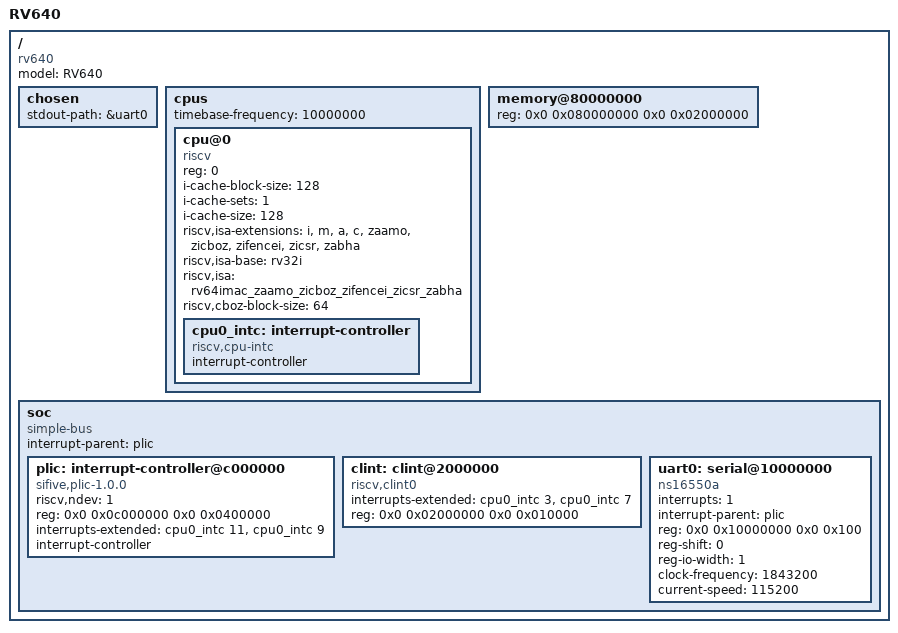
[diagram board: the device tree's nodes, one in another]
/dts-v1/;

/ {
	#address-cells = <2>;
	#size-cells = <2>;
	compatible = "rv640";
	model = "RV640";

	chosen {
		stdout-path = &uart0;
//		bootargs = "earlycon=ns16550a,mmio,0x10000000 console=ttyS0,115200";
	};

	cpus {
		#address-cells = <1>;
		#size-cells = <0>;
		timebase-frequency = <10000000>;

		cpu@0 {
			device_type = "cpu";
			reg = <0>;
			status = "okay";
			compatible = "riscv";
			i-cache-block-size = <128>;
			i-cache-sets = <1>;
			i-cache-size = <128>;
			riscv,isa-extensions = "i", "m", "a", "c", "zaamo", "zicboz", "zifencei", "zicsr", "zabha";
			riscv,isa-base = "rv32i";
			riscv,isa = "rv64imac_zaamo_zicboz_zifencei_zicsr_zabha";
			riscv,cboz-block-size = <64>;
//			mmu-type = "riscv,sv57";
			cpu0_intc: interrupt-controller {
				#interrupt-cells = <1>;
				interrupt-controller;
				compatible = "riscv,cpu-intc";
			};
		};
	};

	memory@80000000 {
		device_type = "memory";
		reg = <0x0 0x080000000 0x0 0x02000000>;
	};

	soc {
		#address-cells = <2>;
		#size-cells = <2>;
		compatible = "simple-bus";
		interrupt-parent = <&plic>;
		ranges;

		plic: interrupt-controller@c000000 {
			riscv,ndev = <1>;
			reg = <0x0 0x0c000000 0x0 0x0400000>;
			interrupts-extended = <&cpu0_intc 11>, <&cpu0_intc 9>;
			interrupt-controller;
			compatible = "sifive,plic-1.0.0";
			#address-cells = <0>;
			#interrupt-cells = <1>;
		};

		clint: clint@2000000 {
			interrupts-extended = <&cpu0_intc 3>, <&cpu0_intc 7>;
			reg = <0x0 0x02000000 0x0 0x010000>;
			compatible = "riscv,clint0";
		};

		uart0: serial@10000000 {
			compatible = "ns16550a";
			interrupts = <1>;
			interrupt-parent = <&plic>;
			reg = <0x0 0x10000000 0x0 0x100>;
			reg-shift = <0>;
			reg-io-width = <1>;
			clock-frequency = <1843200>;
			current-speed = <115200>;
			status = "okay";
		};
	};
};
